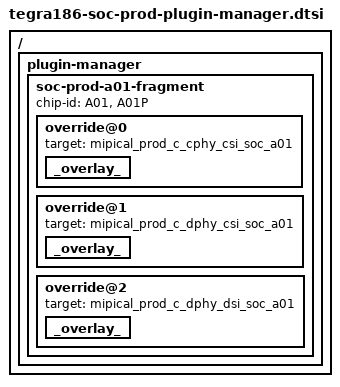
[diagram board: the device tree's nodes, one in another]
/*
 * tegra186-soc-prod-plugin-manager.dtsi: Run time override for the soc
 *	specific prod setting.
 *
 * Copyright (c) 2015-2016, NVIDIA CORPORATION.  All rights reserved.
 *
 * This program is free software; you can redistribute it and/or modify
 * it under the terms of the GNU General Public License as published by
 * the Free Software Foundation; version 2 of the License.
 */

/ {
	plugin-manager {
		soc-prod-a01-fragment {
			chip-id = "A01", "A01P";
			override@0 {
				target = <&mipical_prod_c_cphy_csi_soc_a01>;
				_overlay_ {
					status = "okay";
				};
			};
			override@1 {
				target = <&mipical_prod_c_dphy_csi_soc_a01>;
				_overlay_ {
					status = "okay";
				};
			};
			override@2 {
				target = <&mipical_prod_c_dphy_dsi_soc_a01>;
				_overlay_ {
					status = "okay";
				};
			};
		};
	};
};
